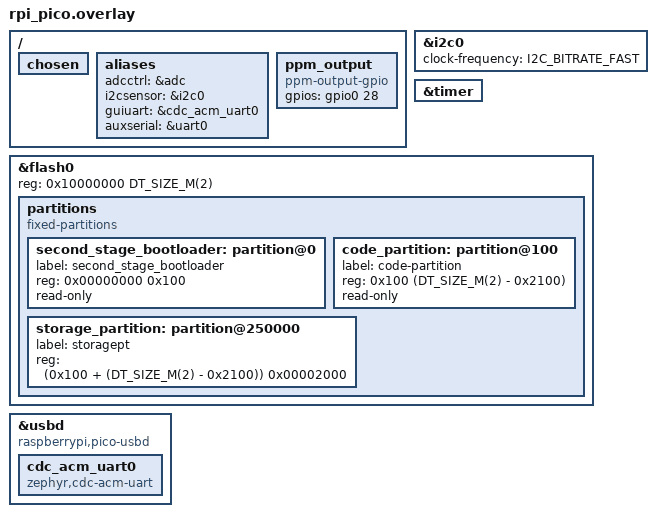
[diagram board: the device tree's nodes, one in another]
/ {
  chosen {
		// Logging Interface
		// zephyr,console = &uart0;
    // zephyr,shell-uart = &uart0;
		/delete-property/ zephyr,shell-uart;
    /delete-property/ zephyr,console;
  };

  aliases {
		adcctrl = &adc;
    i2csensor = &i2c0;
    guiuart = &cdc_acm_uart0;
		auxserial = &uart0;
  };

	// Define the PPM output pin
	ppm_output: ppm_output {
		compatible = "ppm-output-gpio";
		gpios = <&gpio0 28 GPIO_ACTIVE_HIGH>;
	};
};

&i2c0 {
	clock-frequency = <I2C_BITRATE_FAST>;
};

&timer {
	status = "okay";
};

&flash0 {
	reg = <0x10000000 DT_SIZE_M(2)>;

	partitions {
		compatible = "fixed-partitions";
		#address-cells = <1>;
		#size-cells = <1>;

		/* Reserved memory for the second stage bootloader */
		second_stage_bootloader: partition@0 {
			label = "second_stage_bootloader";
			reg = <0x00000000 0x100>;
			read-only;
		};

		/*
		 * Usable flash. Starts at 0x100, after the bootloader. The partition
		 * size is 2MB minus the 0x100 bytes taken by the bootloader.
		 */
		code_partition: partition@100 {
			label = "code-partition";
			reg = <0x100 (DT_SIZE_M(2) - 0x2100)>;
			read-only;
		};

 		storage_partition: partition@250000 {
			label = "storagept";
			reg = <(0x100 + (DT_SIZE_M(2) - 0x2100)) 0x00002000>;
		};
	};
};



zephyr_udc0: &usbd {
	compatible = "raspberrypi,pico-usbd";
	status = "okay";
  cdc_acm_uart0: cdc_acm_uart0 {
		compatible = "zephyr,cdc-acm-uart";
	};

  // Uncomment the below lines for kernel logging to a second USB CDC port
	/*
	cdc_acm_uart1: cdc_acm_uart1 {
		compatible = "zephyr,cdc-acm-uart";
	};
	*/
};

